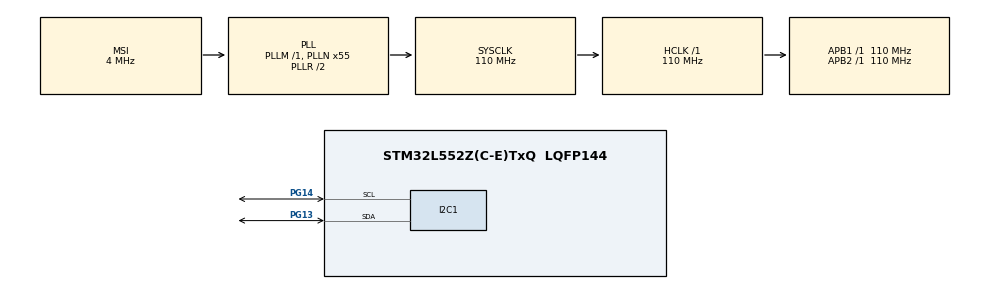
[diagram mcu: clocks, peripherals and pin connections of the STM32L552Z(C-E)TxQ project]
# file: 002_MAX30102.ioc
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I2C1.Timing=0x60514452
Mcu.Family=STM32L5
Mcu.Name=STM32L552Z(C-E)TxQ
Mcu.Package=LQFP144
Mcu.TrustZone=disable
NUCLEO-L552ZE-Q.BUTTON=1
NUCLEO-L552ZE-Q.LD1=true
NUCLEO-L552ZE-Q.LD2=true
NUCLEO-L552ZE-Q.LD3=true
NUCLEO-L552ZE-Q.VCP=true
NVIC.EXTI13_IRQn=true\:0\:0\:false\:false\:true\:false\:true\:true
NVIC.I2C1_ER_IRQn=true\:0\:0\:false\:false\:true\:true\:true\:true
NVIC.I2C1_EV_IRQn=true\:0\:0\:false\:false\:true\:true\:true\:true
NVIC.PriorityGroup=NVIC_PRIORITYGROUP_3
PA13\ (JTMS/SWDIO).Signal=DEBUG_JTMS-SWDIO
PA14\ (JTCK/SWCLK).Signal=DEBUG_JTCK-SWCLK
PB3\ (JTDO/TRACESWO).Signal=DEBUG_JTDO-SWO
PC14-OSC32_IN\ (PC14).Signal=RCC_OSC32_IN
PC15-OSC32_OUT\ (PC15).Signal=RCC_OSC32_OUT
PG13.Mode=I2C
PG13.Signal=I2C1_SDA
PG14.Mode=I2C
PG14.Signal=I2C1_SCL
PG7.Signal=LPUART1_TX
PG8.Signal=LPUART1_RX
ProjectManager.HeapSize=0x200
ProjectManager.StackSize=0x400
ProjectManager.TargetToolchain=STM32CubeIDE
RCC.ADCCLockSelection=RCC_ADCCLKSOURCE_SYSCLK
RCC.ADCFreq_Value=110000000
RCC.AHBFreq_Value=110000000
RCC.APB1Freq_Value=110000000
RCC.APB1TimFreq_Value=110000000
RCC.APB2Freq_Value=110000000
RCC.APB2TimFreq_Value=110000000
RCC.CK48CLockSelection=RCC_USBCLKSOURCE_HSI48
RCC.CortexFreq_Value=110000000
RCC.HCLKFreq_Value=110000000
RCC.HSE_VALUE=8000000
RCC.HSI48_VALUE=48000000
RCC.HSI_VALUE=16000000
RCC.LSE_VALUE=32768
RCC.MSI_VALUE=4000000
RCC.PLLN=55
RCC.PLLSAI1N=24
RCC.RTCClockSelection=RCC_RTCCLKSOURCE_LSE
RCC.SYSCLKFreq_VALUE=110000000
RCC.SYSCLKSource=RCC_SYSCLKSOURCE_PLLCLK
RCC.USBFreq_Value=48000000
RCC.VCOOutputFreq_Value=220000000
VP_ICACHE_VS_ICACHE.Mode=DirectMappedCache
VP_NUCLEO-L552ZE-Q_VS_BSP_COMMON.Mode=COMMON
VP_PWR_VS_DBSignals.Mode=DisableDeadBatterySignals
VP_PWR_VS_SECSignals.Mode=Security/Privilege
board=NUCLEO-L552ZE-Q

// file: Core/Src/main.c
/* USER CODE BEGIN Header */
/**
  ******************************************************************************
  * @file           : main.c
  * @brief          : Main program body
  ******************************************************************************
  * @attention
  *
  * Copyright (c) 2025 STMicroelectronics.
  * All rights reserved.
  *
  * This software is licensed under terms that can be found in the LICENSE file
  * in the root directory of this software component.
  * If no LICENSE file comes with this software, it is provided AS-IS.
  *
  ******************************************************************************
  */
/* USER CODE END Header */
#include "main.h"

/* USER CODE BEGIN Includes */
#include <stdio.h>
#include "dfrobot_bloodoxygen.h"
#include "driver_ssd1306_interface.h"
#include "driver_ssd1306.h"
/* USER CODE END Includes */

COM_InitTypeDef BspCOMInit;
I2C_HandleTypeDef hi2c1;

/* USER CODE BEGIN PV */
volatile I2C_State_t i2c_state = I2C_STATE_READY;
volatile HAL_StatusTypeDef i2c_result = HAL_OK;

/* USER CODE END PV */

void SystemClock_Config(void);
static void MX_GPIO_Init(void);
static void MX_I2C1_Init(void);
static void MX_ICACHE_Init(void);

/* USER CODE BEGIN 0 */
void i2c_scan(I2C_HandleTypeDef *hi2c)
{
    printf("\n=== I2C Scanner ===\n");
    printf("Scanning I2C bus...\n\n");

    uint8_t found_devices = 0;

    for (uint8_t addr = 1; addr < 128; addr++)
    {
        HAL_StatusTypeDef result = HAL_I2C_IsDeviceReady(hi2c, addr << 1, 1, 10);

        if (result == HAL_OK)
        {
            printf("Device found at 0x%02X", addr);

            // Common device identification
            if (addr == 0x3C || addr == 0x3D) {
                printf(" - Likely SSD1306/SSD1309 OLED");
            } else if (addr == 0x57) {
                printf(" - DFRobot Blood Oxygen Sensor");
            }

            printf("\n");
            found_devices++;
        }
    }

    printf("\nTotal devices found: %d\n", found_devices);
}
/* USER CODE END 0 */

int main(void)
{

  /* USER CODE BEGIN 1 */
    ssd1306_handle_t handle;
    uint8_t res;
  /* USER CODE END 1 */

  /* MCU Configuration--------------------------------------------------------*/

  /* Reset of all peripherals, Initializes the Flash interface and the Systick. */
  HAL_Init();

  /* Configure the system clock */
  SystemClock_Config();

  /* Initialize all configured peripherals */
  MX_GPIO_Init();
  MX_I2C1_Init();
  MX_ICACHE_Init();

  /* Initialize leds */
  BSP_LED_Init(LED_GREEN);
  BSP_LED_Init(LED_BLUE);
  BSP_LED_Init(LED_RED);

  /* Initialize USER push-button, will be used to trigger an interrupt each time it's pressed.*/
  BSP_PB_Init(BUTTON_USER, BUTTON_MODE_EXTI);

  /* Initialize COM1 port (115200, 8 bits (7-bit data + 1 stop bit), no parity */
  BspCOMInit.BaudRate   = 115200;
  BspCOMInit.WordLength = COM_WORDLENGTH_8B;
  BspCOMInit.StopBits   = COM_STOPBITS_1;
  BspCOMInit.Parity     = COM_PARITY_NONE;
  BspCOMInit.HwFlowCtl  = COM_HWCONTROL_NONE;
  if (BSP_COM_Init(COM1, &BspCOMInit) != BSP_ERROR_NONE)
  {
    Error_Handler();
  }

  /* Infinite loop */
  /* USER CODE BEGIN WHILE */
  i2c_scan(&hi2c1);

  // Initialize sensor
  if (dfrobot_init(&hi2c1) != 0) {
      printf("Sensor init failed!\n");
      Error_Handler();
  }

  // Wait for sensor to stabilize
  HAL_Delay(2000);

  dfrobot_data_t data;

  /* I2C LCD */
  DRIVER_SSD1306_LINK_INIT(&handle, ssd1306_handle_t);
  DRIVER_SSD1306_LINK_IIC_INIT(&handle, ssd1306_interface_iic_init);
  DRIVER_SSD1306_LINK_IIC_DEINIT(&handle, ssd1306_interface_iic_deinit);
  DRIVER_SSD1306_LINK_IIC_WRITE(&handle, ssd1306_interface_iic_write);
  DRIVER_SSD1306_LINK_SPI_INIT(&handle, ssd1306_interface_spi_init);
  DRIVER_SSD1306_LINK_SPI_DEINIT(&handle, ssd1306_interface_spi_deinit);
  DRIVER_SSD1306_LINK_SPI_WRITE_COMMAND(&handle, ssd1306_interface_spi_write_cmd);
  DRIVER_SSD1306_LINK_SPI_COMMAND_DATA_GPIO_INIT(&handle, ssd1306_interface_spi_cmd_data_gpio_init);
  DRIVER_SSD1306_LINK_SPI_COMMAND_DATA_GPIO_DEINIT(&handle, ssd1306_interface_spi_cmd_data_gpio_deinit);
  DRIVER_SSD1306_LINK_SPI_COMMAND_DATA_GPIO_WRITE(&handle, ssd1306_interface_spi_cmd_data_gpio_write);
  DRIVER_SSD1306_LINK_RESET_GPIO_INIT(&handle, ssd1306_interface_reset_gpio_init);
  DRIVER_SSD1306_LINK_RESET_GPIO_DEINIT(&handle, ssd1306_interface_reset_gpio_deinit);
  DRIVER_SSD1306_LINK_RESET_GPIO_WRITE(&handle, ssd1306_interface_reset_gpio_write);
  DRIVER_SSD1306_LINK_DELAY_MS(&handle, ssd1306_interface_delay_ms);
  DRIVER_SSD1306_LINK_DEBUG_PRINT(&handle, ssd1306_interface_debug_print);

  res = ssd1306_set_interface(&handle, SSD1306_INTERFACE_IIC);
  if (res != 0)
  {
      ssd1306_interface_debug_print("ssd1306: set interface failed.\n");
      return 1;
  }

  res = ssd1306_set_addr_pin(&handle, SSD1306_ADDR_SA0_0);  // address 0x3C
  if (res != 0)
  {
      ssd1306_interface_debug_print("ssd1306: set addr pin failed.\n");
      return 1;
  }

  res = ssd1306_init(&handle);
  if (res != 0)
  {
      ssd1306_interface_debug_print("ssd1306: init failed.\n");
      return 1;
  }

  /* enable charge pump - IMPORTANT */
  printf("enabling charge pump...\n");
  res = ssd1306_set_charge_pump(&handle, SSD1306_CHARGE_PUMP_ENABLE);
  if (res != 0)
  {
      ssd1306_interface_debug_print("ssd1306: set charge pump failed.\n");
      (void)ssd1306_deinit(&handle);
      return 1;
  }

  /* fix upside down display */
  res = ssd1306_set_segment_remap(&handle, SSD1306_SEGMENT_COLUMN_ADDRESS_127);
  if (res != 0)
  {
      ssd1306_interface_debug_print("ssd1306: set segment remap failed.\n");
      (void)ssd1306_deinit(&handle);
      return 1;
  }

  res = ssd1306_set_scan_direction(&handle, SSD1306_SCAN_DIRECTION_COMN_1_START);
  if (res != 0)
  {
      ssd1306_interface_debug_print("ssd1306: set scan direction failed.\n");
      (void)ssd1306_deinit(&handle);
      return 1;
  }

  /* close display */
  res = ssd1306_set_display(&handle, SSD1306_DISPLAY_OFF);
  if (res != 0)
  {
      ssd1306_interface_debug_print("ssd1306: set display failed.\n");
      (void)ssd1306_deinit(&handle);

      return 1;
  }

  /* set column address range */
  res = ssd1306_set_column_address_range(&handle, 0x00, 0x7F);
  if (res != 0)
  {
      ssd1306_interface_debug_print("ssd1306: set column address range failed.\n");
      (void)ssd1306_deinit(&handle);

      return 1;
  }

  /* set page address range */
  res = ssd1306_set_page_address_range(&handle, 0x00, 0x07);
  if (res != 0)
  {
      ssd1306_interface_debug_print("ssd1306: set page address range failed.\n");
      (void)ssd1306_deinit(&handle);

      return 1;
  }

  /* set low column start address */
  res = ssd1306_set_low_column_start_address(&handle, 0x00);
  if (res != 0)
  {
      ssd1306_interface_debug_print("ssd1306: set low column start address failed.\n");
      (void)ssd1306_deinit(&handle);

      return 1;
  }

  /* set high column start address */
  res = ssd1306_set_high_column_start_address(&handle, 0x00);
  if (res != 0)
  {
      ssd1306_interface_debug_print("ssd1306: set high column start address failed.\n");
      (void)ssd1306_deinit(&handle);

      return 1;
  }

  /* set display start line */
  res = ssd1306_set_display_start_line(&handle, 0x00);
  if (res != 0)
  {
      ssd1306_interface_debug_print("ssd1306: set display start line failed.\n");
      (void)ssd1306_deinit(&handle);

      return 1;
  }

  /* set fade blinking mode */
  res = ssd1306_set_fade_blinking_mode(&handle, SSD1306_FADE_BLINKING_MODE_DISABLE, 0x00);
  if (res != 0)
  {
      ssd1306_interface_debug_print("ssd1306: set fade blinking failed.\n");
      (void)ssd1306_deinit(&handle);

      return 1;
  }

  res = ssd1306_set_display(&handle, SSD1306_DISPLAY_ON);
  if (res != 0)
  {
      ssd1306_interface_debug_print("ssd1306: set display failed.\n");
      (void)ssd1306_deinit(&handle);

      return 1;
  }

  res = ssd1306_clear(&handle);
  if (res != 0)
  {
      ssd1306_interface_debug_print("ssd1306: clear failed.\n");
      (void)ssd1306_deinit(&handle);
      return 1;
  }

  printf("LCD initialization complete!\n");

  while (1)
  {
      char display_buf[32];

      // Read sensor data
      if (dfrobot_read_data(&hi2c1, &data) == 0) {
          if (data.spo2 > 0) {
              printf("SpO2: %d%%\n", data.spo2);
          } else {
              printf("SpO2: No finger detected\n");
          }

          if (data.heartbeat > 0) {
              printf("Heart Rate: %ld BPM\n", data.heartbeat);
          } else {
              printf("Heart Rate: No finger detected\n");
          }
      }

      // Read temperature
      float temp = dfrobot_read_temperature(&hi2c1);
      if (temp > -999.0f) {
          printf("Temperature: %.2f°C\n", temp);
      }

      printf("---\n");

      // update LCD with sensor data
      ssd1306_clear(&handle);

      // line 1: Title
      ssd1306_gram_write_string(&handle, 0, 0, "Blood Oxygen", 12, 1, SSD1306_FONT_12);

      // line 2: SpO2
      if (data.spo2 > 0) {
          snprintf(display_buf, sizeof(display_buf), "SpO2: %d%%", data.spo2);
      } else {
          snprintf(display_buf, sizeof(display_buf), "SpO2: --");
      }
      ssd1306_gram_write_string(&handle, 0, 16, display_buf, (uint16_t)strlen(display_buf), 1, SSD1306_FONT_12);

      // line 3: Heart Rate
      if (data.heartbeat > 0) {
          snprintf(display_buf, sizeof(display_buf), "HR: %ld BPM", data.heartbeat);
      } else {
          snprintf(display_buf, sizeof(display_buf), "HR: --");
      }
      ssd1306_gram_write_string(&handle, 0, 32, display_buf, (uint16_t)strlen(display_buf), 1, SSD1306_FONT_12);

      // line 4: Temperature
      if (temp > -999.0f) {
          snprintf(display_buf, sizeof(display_buf), "Temp: %.1fC", temp);
      } else {
          snprintf(display_buf, sizeof(display_buf), "Temp: --");
      }
      ssd1306_gram_write_string(&handle, 0, 48, display_buf, (uint16_t)strlen(display_buf), 1, SSD1306_FONT_12);

      // Update display
      ssd1306_gram_update(&handle);

      HAL_Delay(1000);  // Update every second
    /* USER CODE END WHILE */

  }
}

void SystemClock_Config(void)
{
  RCC_OscInitTypeDef RCC_OscInitStruct = {0};
  RCC_ClkInitTypeDef RCC_ClkInitStruct = {0};

  /** Configure the main internal regulator output voltage
  */
  if (HAL_PWREx_ControlVoltageScaling(PWR_REGULATOR_VOLTAGE_SCALE0) != HAL_OK)
  {
    Error_Handler();
  }

  /** Initializes the RCC Oscillators according to the specified parameters
  * in the RCC_OscInitTypeDef structure.
  */
  RCC_OscInitStruct.OscillatorType = RCC_OSCILLATORTYPE_MSI;
  RCC_OscInitStruct.MSIState = RCC_MSI_ON;
  RCC_OscInitStruct.MSICalibrationValue = RCC_MSICALIBRATION_DEFAULT;
  RCC_OscInitStruct.MSIClockRange = RCC_MSIRANGE_6;
  RCC_OscInitStruct.PLL.PLLState = RCC_PLL_ON;
  RCC_OscInitStruct.PLL.PLLSource = RCC_PLLSOURCE_MSI;
  RCC_OscInitStruct.PLL.PLLM = 1;
  RCC_OscInitStruct.PLL.PLLN = 55;
  RCC_OscInitStruct.PLL.PLLP = RCC_PLLP_DIV7;
  RCC_OscInitStruct.PLL.PLLQ = RCC_PLLQ_DIV2;
  RCC_OscInitStruct.PLL.PLLR = RCC_PLLR_DIV2;
  if (HAL_RCC_OscConfig(&RCC_OscInitStruct) != HAL_OK)
  {
    Error_Handler();
  }

  /** Initializes the CPU, AHB and APB buses clocks
  */
  RCC_ClkInitStruct.ClockType = RCC_CLOCKTYPE_HCLK|RCC_CLOCKTYPE_SYSCLK
                              |RCC_CLOCKTYPE_PCLK1|RCC_CLOCKTYPE_PCLK2;
  RCC_ClkInitStruct.SYSCLKSource = RCC_SYSCLKSOURCE_PLLCLK;
  RCC_ClkInitStruct.AHBCLKDivider = RCC_SYSCLK_DIV1;
  RCC_ClkInitStruct.APB1CLKDivider = RCC_HCLK_DIV1;
  RCC_ClkInitStruct.APB2CLKDivider = RCC_HCLK_DIV1;

  if (HAL_RCC_ClockConfig(&RCC_ClkInitStruct, FLASH_LATENCY_5) != HAL_OK)
  {
    Error_Handler();
  }
}

static void MX_I2C1_Init(void)
{

  hi2c1.Instance = I2C1;
  hi2c1.Init.Timing = 0x60514452;
  hi2c1.Init.OwnAddress1 = 0;
  hi2c1.Init.AddressingMode = I2C_ADDRESSINGMODE_7BIT;
  hi2c1.Init.DualAddressMode = I2C_DUALADDRESS_DISABLE;
  hi2c1.Init.OwnAddress2 = 0;
  hi2c1.Init.OwnAddress2Masks = I2C_OA2_NOMASK;
  hi2c1.Init.GeneralCallMode = I2C_GENERALCALL_DISABLE;
  hi2c1.Init.NoStretchMode = I2C_NOSTRETCH_DISABLE;
  if (HAL_I2C_Init(&hi2c1) != HAL_OK)
  {
    Error_Handler();
  }

  /** Configure Analogue filter
  */
  if (HAL_I2CEx_ConfigAnalogFilter(&hi2c1, I2C_ANALOGFILTER_ENABLE) != HAL_OK)
  {
    Error_Handler();
  }

  /** Configure Digital filter
  */
  if (HAL_I2CEx_ConfigDigitalFilter(&hi2c1, 0) != HAL_OK)
  {
    Error_Handler();
  }
  /* USER CODE BEGIN I2C1_Init 2 */

  // Enable I2C interrupts
  HAL_NVIC_SetPriority(I2C1_EV_IRQn, 2, 0);
  HAL_NVIC_EnableIRQ(I2C1_EV_IRQn);
  HAL_NVIC_SetPriority(I2C1_ER_IRQn, 2, 0);
  HAL_NVIC_EnableIRQ(I2C1_ER_IRQn);

  /* USER CODE END I2C1_Init 2 */

}

static void MX_ICACHE_Init(void)
{

  /** Enable instruction cache in 1-way (direct mapped cache)
  */
  if (HAL_ICACHE_ConfigAssociativityMode(ICACHE_1WAY) != HAL_OK)
  {
    Error_Handler();
  }
  if (HAL_ICACHE_Enable() != HAL_OK)
  {
    Error_Handler();
  }

}

static void MX_GPIO_Init(void)
{

  /* GPIO Ports Clock Enable */
  __HAL_RCC_GPIOC_CLK_ENABLE();
  __HAL_RCC_GPIOA_CLK_ENABLE();
  __HAL_RCC_GPIOG_CLK_ENABLE();
  HAL_PWREx_EnableVddIO2();
  __HAL_RCC_GPIOB_CLK_ENABLE();

}

/* USER CODE BEGIN 4 */

/**
 * @brief I2C Memory Transmit Complete Callback
 */
void HAL_I2C_MemTxCpltCallback(I2C_HandleTypeDef *hi2c)
{
    if (hi2c->Instance == I2C1) {
        i2c_state = I2C_STATE_READY;
        i2c_result = HAL_OK;
    }
}

/**
 * @brief I2C Memory Receive Complete Callback
 */
void HAL_I2C_MemRxCpltCallback(I2C_HandleTypeDef *hi2c)
{
    if (hi2c->Instance == I2C1) {
        i2c_state = I2C_STATE_READY;
        i2c_result = HAL_OK;
    }
}

/**
 * @brief I2C Master Transmit Complete Callback
 */
void HAL_I2C_MasterTxCpltCallback(I2C_HandleTypeDef *hi2c)
{
    if (hi2c->Instance == I2C1) {
        i2c_state = I2C_STATE_READY;
        i2c_result = HAL_OK;
    }
}

/**
 * @brief I2C Master Receive Complete Callback
 */
void HAL_I2C_MasterRxCpltCallback(I2C_HandleTypeDef *hi2c)
{
    if (hi2c->Instance == I2C1) {
        i2c_state = I2C_STATE_READY;
        i2c_result = HAL_OK;
    }
}

/**
 * @brief I2C Error Callback
 */
void HAL_I2C_ErrorCallback(I2C_HandleTypeDef *hi2c)
{
    if (hi2c->Instance == I2C1) {
        i2c_state = I2C_STATE_ERROR;
        i2c_result = HAL_ERROR;
    }
}

/* USER CODE END 4 */

void Error_Handler(void)
{
  __disable_irq();
  while (1)
  {
  }
}
